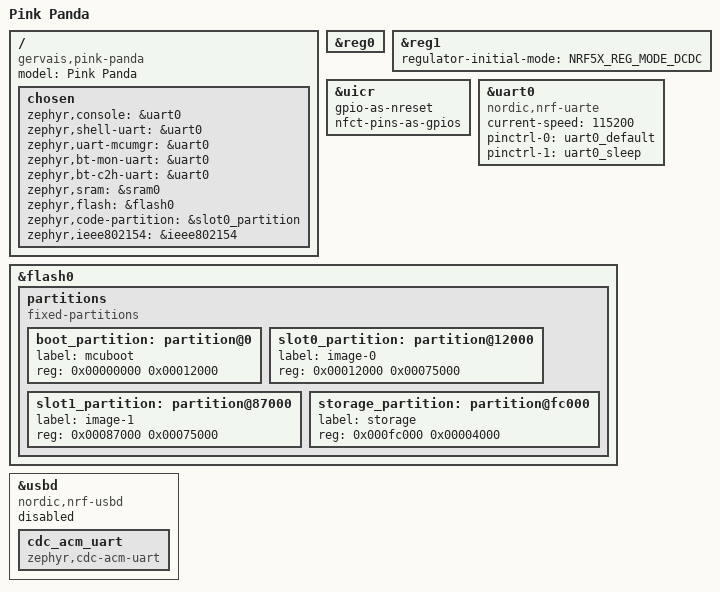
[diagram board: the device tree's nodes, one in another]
/dts-v1/;
#include <nordic/nrf52840_qiaa.dtsi>
#include "pink_panda-pinctrl.dtsi"

/ {
	model = "Pink Panda";
	compatible = "gervais,pink-panda";

	chosen {
		zephyr,console = &uart0;
		zephyr,shell-uart = &uart0;
		zephyr,uart-mcumgr = &uart0;
		zephyr,bt-mon-uart = &uart0;
		zephyr,bt-c2h-uart = &uart0;
		zephyr,sram = &sram0;
		zephyr,flash = &flash0;
		zephyr,code-partition = &slot0_partition;
		zephyr,ieee802154 = &ieee802154;
	};
};

&reg0 {
	status = "okay";
};

&reg1 {
	regulator-initial-mode = <NRF5X_REG_MODE_DCDC>;
};

&uicr {
	gpio-as-nreset;
	nfct-pins-as-gpios;
};

&uart0 {
	compatible = "nordic,nrf-uarte";
	status = "okay";
	current-speed = <115200>;
	pinctrl-0 = <&uart0_default>;
	pinctrl-1 = <&uart0_sleep>;
	pinctrl-names = "default", "sleep";
};

&flash0 {
	partitions {
		compatible = "fixed-partitions";
		#address-cells = <1>;
		#size-cells = <1>;

		/* The size of this partition ensures that MCUBoot can be built
		 * with an RTT console, CDC ACM support, and w/o optimizations.
		 */
		boot_partition: partition@0 {
			label = "mcuboot";
			reg = <0x00000000 0x00012000>;
		};

		slot0_partition: partition@12000 {
			label = "image-0";
			reg = <0x00012000 0x00075000>;
		};

		slot1_partition: partition@87000 {
			label = "image-1";
			reg = <0x00087000 0x00075000>;
		};

		storage_partition: partition@fc000 {
			label = "storage";
			reg = <0x000fc000 0x00004000>;
		};
	};
};

zephyr_udc0: &usbd {
	compatible = "nordic,nrf-usbd";
	status = "disabled";

	cdc_acm_uart: cdc_acm_uart {
		compatible = "zephyr,cdc-acm-uart";
	};
};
